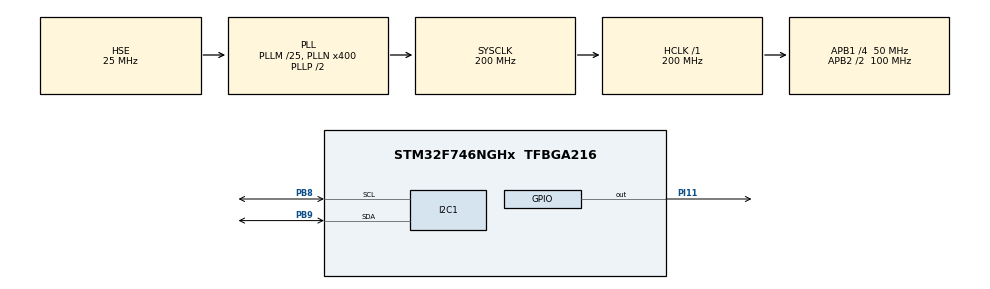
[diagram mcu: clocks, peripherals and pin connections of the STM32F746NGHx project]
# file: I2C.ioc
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I2C1.Timing=0x00C0EAFF
Mcu.Family=STM32F7
Mcu.Name=STM32F746NGHx
Mcu.Package=TFBGA216
NVIC.I2C1_ER_IRQn=true\:0\:0\:false\:false\:true\:true
NVIC.I2C1_EV_IRQn=true\:0\:0\:false\:false\:true\:true
NVIC.PriorityGroup=NVIC_PRIORITYGROUP_4
NVIC.TIM1_UP_TIM10_IRQn=true\:0\:0\:false\:false\:true\:true
PB8.Mode=I2C
PB8.Signal=I2C1_SCL
PB9.Mode=I2C
PB9.Signal=I2C1_SDA
PH0/OSC_IN.Mode=HSE-External-Oscillator
PH0/OSC_IN.Signal=RCC_OSC_IN
PH1/OSC_OUT.Mode=HSE-External-Oscillator
PH1/OSC_OUT.Signal=RCC_OSC_OUT
PI11.Signal=GPIO_Output
ProjectManager.HeapSize=0x200
ProjectManager.StackSize=0x400
ProjectManager.TargetToolchain=MDK-ARM V5
RCC.AHBFreq_Value=200000000
RCC.APB1CLKDivider=RCC_HCLK_DIV4
RCC.APB1Freq_Value=50000000
RCC.APB1TimFreq_Value=100000000
RCC.APB2CLKDivider=RCC_HCLK_DIV2
RCC.APB2Freq_Value=100000000
RCC.APB2TimFreq_Value=200000000
RCC.CortexFreq_Value=200000000
RCC.HCLKFreq_Value=200000000
RCC.HSE_VALUE=25000000
RCC.HSI_VALUE=16000000
RCC.LSE_VALUE=32768
RCC.PLL48CLockSelection=RCC_CLK48SOURCE_PLLSAIP
RCC.PLLI2SN=100
RCC.PLLM=25
RCC.PLLN=400
RCC.PLLQ=9
RCC.PLLSAIN=384
RCC.PLLSAIP=RCC_PLLSAIP_DIV8
RCC.PLLSAIR=5
RCC.PLLSAIRDiv=RCC_PLLSAIDIVR_8
RCC.PLLSourceVirtual=RCC_PLLSOURCE_HSE
RCC.SDMMCClockSelection=RCC_SDMMC1CLKSOURCE_CLK48
RCC.SYSCLKFreq_VALUE=200000000
RCC.SYSCLKSource=RCC_SYSCLKSOURCE_PLLCLK
RCC.USBFreq_Value=48000000
RCC.VCOOutputFreq_Value=400000000
TIM1.AutoReloadPreload=TIM_AUTORELOAD_PRELOAD_ENABLE
TIM1.Period=65534
TIM1.Prescaler=3052
TIM1.TIM_MasterOutputTrigger=TIM_TRGO_UPDATE
TIM1.TIM_MasterOutputTrigger2=TIM_TRGO2_UPDATE
VP_TIM1_VS_ClockSourceINT.Mode=Internal
board=32F746GDISCOVERY

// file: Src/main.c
/**
  ******************************************************************************
  * @file           : main.c
  * @brief          : Main program body
  ******************************************************************************
  ** This notice applies to any and all portions of this file
  * that are not between comment pairs USER CODE BEGIN and
  * USER CODE END. Other portions of this file, whether
  * inserted by the user or by software development tools
  * are owned by their respective copyright owners.
  *
  * COPYRIGHT(c) 2018 STMicroelectronics
  *
  * Redistribution and use in source and binary forms, with or without modification,
  * are permitted provided that the following conditions are met:
  *   1. Redistributions of source code must retain the above copyright notice,
  *      this list of conditions and the following disclaimer.
  *   2. Redistributions in binary form must reproduce the above copyright notice,
  *      this list of conditions and the following disclaimer in the documentation
  *      and/or other materials provided with the distribution.
  *   3. Neither the name of STMicroelectronics nor the names of its contributors
  *      may be used to endorse or promote products derived from this software
  *      without specific prior written permission.
  *
  * THIS SOFTWARE IS PROVIDED BY THE COPYRIGHT HOLDERS AND CONTRIBUTORS "AS IS"
  * AND ANY EXPRESS OR IMPLIED WARRANTIES, INCLUDING, BUT NOT LIMITED TO, THE
  * IMPLIED WARRANTIES OF MERCHANTABILITY AND FITNESS FOR A PARTICULAR PURPOSE ARE
  * DISCLAIMED. IN NO EVENT SHALL THE COPYRIGHT HOLDER OR CONTRIBUTORS BE LIABLE
  * FOR ANY DIRECT, INDIRECT, INCIDENTAL, SPECIAL, EXEMPLARY, OR CONSEQUENTIAL
  * DAMAGES (INCLUDING, BUT NOT LIMITED TO, PROCUREMENT OF SUBSTITUTE GOODS OR
  * SERVICES; LOSS OF USE, DATA, OR PROFITS; OR BUSINESS INTERRUPTION) HOWEVER
  * CAUSED AND ON ANY THEORY OF LIABILITY, WHETHER IN CONTRACT, STRICT LIABILITY,
  * OR TORT (INCLUDING NEGLIGENCE OR OTHERWISE) ARISING IN ANY WAY OUT OF THE USE
  * OF THIS SOFTWARE, EVEN IF ADVISED OF THE POSSIBILITY OF SUCH DAMAGE.
  *
  ******************************************************************************
  */
#include "main.h"
#include "stm32f7xx_hal.h"

/* USER CODE BEGIN Includes */
#include <math.h>
#include <stdlib.h>
#define RAD_TO_DEG 57.295779513082320876798154814105
/* USER CODE END Includes */

I2C_HandleTypeDef hi2c1;

TIM_HandleTypeDef htim1;

/* USER CODE BEGIN PV */
/* Private variables ---------------------------------------------------------*/
  volatile float  gyro_x,gyro_y,gyro_z,accel_x=0,accel_y=0,accel_z=0,temp;
	float Xa,Ya,Za,t;
	float Xg=0,Yg=0,Zg=0;
	double tot;
	float angle1;
	float angle_gyro=0,del_x;
	int set_gyro_angle=0;
	int count;
/* USER CODE END PV */

void SystemClock_Config(void);
static void MX_GPIO_Init(void);
static void MX_I2C1_Init(void);
static void MX_TIM1_Init(void);

/* USER CODE BEGIN PFP */
/* Private function prototypes -----------------------------------------------*/

/* USER CODE END PFP */

/* USER CODE BEGIN 0 */
void MPU_Init(uint16_t slave_address);
void MPU_GET_VALUE(uint16_t slave_address);
void MPU_SHOWDATA(void);

/* USER CODE END 0 */

int main(void)
{

  /* MCU Configuration----------------------------------------------------------*/

  /* Reset of all peripherals, Initializes the Flash interface and the Systick. */
  HAL_Init();

  /* Configure the system clock */
  SystemClock_Config();

  /* Initialize all configured peripherals */
  MX_GPIO_Init();
  MX_I2C1_Init();
  MX_TIM1_Init();
  /* USER CODE BEGIN 2 */
	if(HAL_I2C_IsDeviceReady(&hi2c1,0x68,3,200)==HAL_OK)
	{
		HAL_GPIO_WritePin(GPIOI,GPIO_PIN_11,GPIO_PIN_SET);

	}
	MPU_Init(0x68);
	HAL_TIM_Base_Start_IT( &htim1);
  /* USER CODE END 2 */

  /* Infinite loop */
  /* USER CODE BEGIN WHILE */
	TIM1->CNT =0;
  while (1)
  {

  /* USER CODE END WHILE */

  /* USER CODE BEGIN 3 */
		MPU_SHOWDATA();

  }
  /* USER CODE END 3 */

}

void SystemClock_Config(void)
{

  RCC_OscInitTypeDef RCC_OscInitStruct;
  RCC_ClkInitTypeDef RCC_ClkInitStruct;
  RCC_PeriphCLKInitTypeDef PeriphClkInitStruct;

    /**Configure the main internal regulator output voltage
    */
  __HAL_RCC_PWR_CLK_ENABLE();

  __HAL_PWR_VOLTAGESCALING_CONFIG(PWR_REGULATOR_VOLTAGE_SCALE1);

    /**Initializes the CPU, AHB and APB busses clocks
    */
  RCC_OscInitStruct.OscillatorType = RCC_OSCILLATORTYPE_HSE;
  RCC_OscInitStruct.HSEState = RCC_HSE_ON;
  RCC_OscInitStruct.PLL.PLLState = RCC_PLL_ON;
  RCC_OscInitStruct.PLL.PLLSource = RCC_PLLSOURCE_HSE;
  RCC_OscInitStruct.PLL.PLLM = 25;
  RCC_OscInitStruct.PLL.PLLN = 400;
  RCC_OscInitStruct.PLL.PLLP = RCC_PLLP_DIV2;
  RCC_OscInitStruct.PLL.PLLQ = 9;
  if (HAL_RCC_OscConfig(&RCC_OscInitStruct) != HAL_OK)
  {
    _Error_Handler(__FILE__, __LINE__);
  }

    /**Activate the Over-Drive mode
    */
  if (HAL_PWREx_EnableOverDrive() != HAL_OK)
  {
    _Error_Handler(__FILE__, __LINE__);
  }

    /**Initializes the CPU, AHB and APB busses clocks
    */
  RCC_ClkInitStruct.ClockType = RCC_CLOCKTYPE_HCLK|RCC_CLOCKTYPE_SYSCLK
                              |RCC_CLOCKTYPE_PCLK1|RCC_CLOCKTYPE_PCLK2;
  RCC_ClkInitStruct.SYSCLKSource = RCC_SYSCLKSOURCE_PLLCLK;
  RCC_ClkInitStruct.AHBCLKDivider = RCC_SYSCLK_DIV1;
  RCC_ClkInitStruct.APB1CLKDivider = RCC_HCLK_DIV4;
  RCC_ClkInitStruct.APB2CLKDivider = RCC_HCLK_DIV2;

  if (HAL_RCC_ClockConfig(&RCC_ClkInitStruct, FLASH_LATENCY_6) != HAL_OK)
  {
    _Error_Handler(__FILE__, __LINE__);
  }

  PeriphClkInitStruct.PeriphClockSelection = RCC_PERIPHCLK_I2C1;
  PeriphClkInitStruct.I2c1ClockSelection = RCC_I2C1CLKSOURCE_PCLK1;
  if (HAL_RCCEx_PeriphCLKConfig(&PeriphClkInitStruct) != HAL_OK)
  {
    _Error_Handler(__FILE__, __LINE__);
  }

    /**Configure the Systick interrupt time
    */
  HAL_SYSTICK_Config(HAL_RCC_GetHCLKFreq()/1000);

    /**Configure the Systick
    */
  HAL_SYSTICK_CLKSourceConfig(SYSTICK_CLKSOURCE_HCLK);

  /* SysTick_IRQn interrupt configuration */
  HAL_NVIC_SetPriority(SysTick_IRQn, 0, 0);
}

/* I2C1 init function */
static void MX_I2C1_Init(void)
{

  hi2c1.Instance = I2C1;
  hi2c1.Init.Timing = 0x00C0EAFF;
  hi2c1.Init.OwnAddress1 = 0;
  hi2c1.Init.AddressingMode = I2C_ADDRESSINGMODE_7BIT;
  hi2c1.Init.DualAddressMode = I2C_DUALADDRESS_DISABLE;
  hi2c1.Init.OwnAddress2 = 0;
  hi2c1.Init.OwnAddress2Masks = I2C_OA2_NOMASK;
  hi2c1.Init.GeneralCallMode = I2C_GENERALCALL_DISABLE;
  hi2c1.Init.NoStretchMode = I2C_NOSTRETCH_DISABLE;
  if (HAL_I2C_Init(&hi2c1) != HAL_OK)
  {
    _Error_Handler(__FILE__, __LINE__);
  }

    /**Configure Analogue filter
    */
  if (HAL_I2CEx_ConfigAnalogFilter(&hi2c1, I2C_ANALOGFILTER_ENABLE) != HAL_OK)
  {
    _Error_Handler(__FILE__, __LINE__);
  }

    /**Configure Digital filter
    */
  if (HAL_I2CEx_ConfigDigitalFilter(&hi2c1, 0) != HAL_OK)
  {
    _Error_Handler(__FILE__, __LINE__);
  }

}

/* TIM1 init function */

static void MX_TIM1_Init(void)
{

  TIM_ClockConfigTypeDef sClockSourceConfig;
  TIM_MasterConfigTypeDef sMasterConfig;

  htim1.Instance = TIM1;
  htim1.Init.Prescaler = 3052;
  htim1.Init.CounterMode = TIM_COUNTERMODE_UP;
  htim1.Init.Period = 65534;
  htim1.Init.ClockDivision = TIM_CLOCKDIVISION_DIV1;
  htim1.Init.RepetitionCounter = 0;
  htim1.Init.AutoReloadPreload = TIM_AUTORELOAD_PRELOAD_ENABLE;
  if (HAL_TIM_Base_Init(&htim1) != HAL_OK)
  {
    _Error_Handler(__FILE__, __LINE__);
  }

  sClockSourceConfig.ClockSource = TIM_CLOCKSOURCE_INTERNAL;
  if (HAL_TIM_ConfigClockSource(&htim1, &sClockSourceConfig) != HAL_OK)
  {
    _Error_Handler(__FILE__, __LINE__);
  }

  sMasterConfig.MasterOutputTrigger = TIM_TRGO_UPDATE;
  sMasterConfig.MasterOutputTrigger2 = TIM_TRGO2_UPDATE;
  sMasterConfig.MasterSlaveMode = TIM_MASTERSLAVEMODE_DISABLE;
  if (HAL_TIMEx_MasterConfigSynchronization(&htim1, &sMasterConfig) != HAL_OK)
  {
    _Error_Handler(__FILE__, __LINE__);
  }

}

/** Configure pins as
        * Analog
        * Input
        * Output
        * EVENT_OUT
        * EXTI
*/
static void MX_GPIO_Init(void)
{

  GPIO_InitTypeDef GPIO_InitStruct;

  /* GPIO Ports Clock Enable */
  __HAL_RCC_GPIOB_CLK_ENABLE();
  __HAL_RCC_GPIOI_CLK_ENABLE();
  __HAL_RCC_GPIOH_CLK_ENABLE();

  /*Configure GPIO pin Output Level */
  HAL_GPIO_WritePin(GPIOI, GPIO_PIN_11, GPIO_PIN_RESET);

  /*Configure GPIO pin : PI11 */
  GPIO_InitStruct.Pin = GPIO_PIN_11;
  GPIO_InitStruct.Mode = GPIO_MODE_OUTPUT_PP;
  GPIO_InitStruct.Pull = GPIO_NOPULL;
  GPIO_InitStruct.Speed = GPIO_SPEED_FREQ_LOW;
  HAL_GPIO_Init(GPIOI, &GPIO_InitStruct);

}

/* USER CODE BEGIN 4 */

void MPU_Init(uint16_t slave_address)
{

	uint8_t buffer[2]={0x19,0x00};//Gyroscope output value is 8MHZ so sample rate is 1MHz

  HAL_I2C_Master_Transmit(&hi2c1,slave_address<<1,(uint8_t *)&buffer,2,200);

	buffer[0] = 0x6B;//Power Managment system
	buffer[1] = 0x00;//Internal clock of 8MHz oscillator
  HAL_I2C_Master_Transmit(&hi2c1,slave_address<<1,(uint8_t *)&buffer,2,200);

	//Configure
	buffer[0] = 0x1A;
	buffer[1] = 0x03;//Digital low pass filter Gyro = 8kHz
  HAL_I2C_Master_Transmit(&hi2c1,slave_address<<1,(uint8_t *)&buffer,2,200);

	//Configure Gyro
	buffer[0] = 0x1B;
	buffer[1] = 0x00; //
  HAL_I2C_Master_Transmit(&hi2c1,slave_address<<1,(uint8_t *)&buffer,2,200);

	//Configure Accelerometer
	buffer[0] = 0x1C;
	buffer[1] = 0x00;
	HAL_I2C_Master_Transmit(&hi2c1,slave_address<<1,(uint8_t *)&buffer,2,200);
	//Interrupt Enable
	buffer[0] = 0x38;
	buffer[1] = 0x01;
  HAL_I2C_Master_Transmit(&hi2c1,slave_address<<1,(uint8_t *)&buffer,2,200);

}

void MPU_GET_VALUE(uint16_t slave_address)
{
	uint8_t buffer=0x3B;
	uint8_t data[14];
	HAL_I2C_Master_Transmit(&hi2c1,slave_address<<1,(uint8_t *)&buffer,1,200);
	HAL_Delay(20);
	HAL_I2C_Master_Receive(&hi2c1,slave_address<<1,(uint8_t *)&data,14,200);
	accel_x = ~((((int)data[0]<<8|((int)data[1])))-1);//2`s complements value to signed value value
	accel_y = ~((((int)data[2]<<8|((int)data[3])))-1);
	accel_z =~((((int)data[4]<<8|((int)data[5])))-1);
	temp = ((data[6]<<8)|(data[7]));
	gyro_x = ~((((int)data[8]<<8|((int)data[9])))-1);
	gyro_y = ~((((int)data[10]<<8|((int)data[11])))-1);
	gyro_z = ~((((int)data[12]<<8|((int)data[13])))-1);

}

void MPU_SHOWDATA(void)
{
    MPU_GET_VALUE(0x68);
     Xa = accel_x/16384;								/* Divide raw value by sensitivity scale factor to get real values */
     Ya = accel_y/16384;
     Za = accel_z/16384;

     Xg = gyro_x/131;
     Yg = gyro_y/131;
     Zg = gyro_z/131;

//     del_x = (double)(TIM1->CNT) / 65534 ;
//		count = del_x;
//		 TIM1->CNT =0;
//     angle_gyro += Yg*del_x;
//     tot = sqrt(Xa*Xa+Ya*Ya+Za*Za);
//     angle1 = asin((float)Xa/tot)*57.29577;
//
//     if(set_gyro_angle)
//     {
//	     angle_gyro = angle_gyro*0.96 +angle1*0.04;
//     }
//     else
//     {
//	     angle_gyro = angle1;
//	     set_gyro_angle =1;
//     }

}

void HAL_TIM_PeriodElapsedCallback(TIM_HandleTypeDef *htim)
{

}

/* USER CODE END 4 */

void _Error_Handler(char *file, int line)
{
  while(1)
  {
  }
}

/************************ (C) COPYRIGHT STMicroelectronics *****END OF FILE****/
